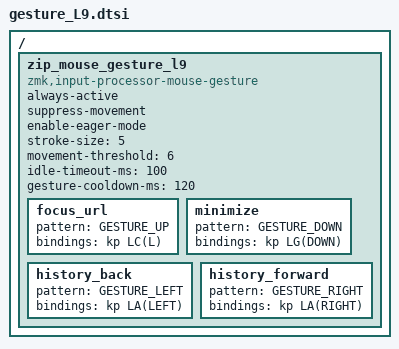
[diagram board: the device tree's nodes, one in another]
#include <dt-bindings/zmk/mouse-gesture.h>

/ {
    zip_mouse_gesture_l9: zip_mouse_gesture_l9 {
        compatible = "zmk,input-processor-mouse-gesture";
        #input-processor-cells = <0>;

        always-active;        // レイヤータップで遷移するため起動キー不要
        suppress-movement;    // このレイヤー中はカーソルを固定する
        enable-eager-mode;
        stroke-size = <5>;
        movement-threshold = <6>;
        idle-timeout-ms = <100>;
        gesture-cooldown-ms = <120>;

        // ブラウザ/ウィンドウ操作
        focus_url        { pattern = <GESTURE_UP>;    bindings = <&kp LC(L)>;     };
        minimize         { pattern = <GESTURE_DOWN>;  bindings = <&kp LG(DOWN)>;  };
        history_back     { pattern = <GESTURE_LEFT>;  bindings = <&kp LA(LEFT)>;  };
        history_forward  { pattern = <GESTURE_RIGHT>; bindings = <&kp LA(RIGHT)>; };
    };
};
